# ATmega16HVBrevB device description
Architecture: AVR8; Family: megaAVR
Registers are 8-bit, access not given, no defined reset value unless marked. A register's access mark holds for its fields unless they carry their own. Offsets are from the block's base; [hi:lo] are bit positions.

## CELL_BALANCING
Instances: CELL_BALANCING 0x00
0xF1 CBCR — Cell Balancing Control Register
  [3:0] CBE (bit 1 of the value upward) — Cell Balancing Enables

## BATTERY_PROTECTION
Instances: BATTERY_PROTECTION 0x00
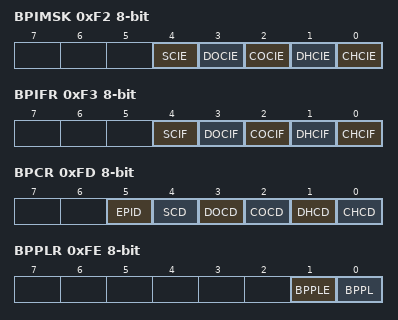
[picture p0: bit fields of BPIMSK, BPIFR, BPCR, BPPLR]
0xF2 BPIMSK — Battery Protection Interrupt Mask Register
  [4] SCIE — Short-circuit Protection Activated Interrupt Enable
  [3] DOCIE — Discharge Over-current Protection Activated Interrupt Enable
  [2] COCIE — Charge Over-current Protection Activated Interrupt Enable
  [1] DHCIE — Discharger High-current Protection Activated Interrupt
  [0] CHCIE — Charger High-current Protection Activated Interrupt
0xF3 BPIFR — Battery Protection Interrupt Flag Register
  [4] SCIF — Short-circuit Protection Activated Interrupt Flag
  [3] DOCIF — Discharge Over-current Protection Activated Interrupt Flag
  [2] COCIF — Charge Over-current Protection Activated Interrupt Flag
  [1] DHCIF — Disharge High-current Protection Activated Interrupt
  [0] CHCIF — Charge High-current Protection Activated Interrupt
0xF5 BPSCD — Battery Protection Short-Circuit Detection Level Register
  [7:0] SCDL — Battery Protection Short-Circuit Detection Level Register bits
0xF6 BPDOCD — Battery Protection Discharge-Over-current Detection Level Register
  [7:0] DOCDL — Battery Protection Discharge-Over-current Detection Level bits
0xF7 BPCOCD — Battery Protection Charge-Over-current Detection Level Register
  [7:0] COCDL — Battery Protection Charge-Over-current Detection Level bits
0xF8 BPDHCD — Battery Protection Discharge-High-current Detection Level Register
  [7:0] DHCDL — Battery Protection Discharge-High-current Detection Level bits
0xF9 BPCHCD — Battery Protection Charge-High-current Detection Level Register
  [7:0] CHCDL — Battery Protection Charge-High-current Detection Level bits
0xFA BPSCTR — Battery Protection Short-current Timing Register
  [6:0] SCPT — Battery Protection Short-current Timing bits
0xFB BPOCTR — Battery Protection Over-current Timing Register
  [5:0] OCPT — Battery Protection Over-current Timing bits
0xFC BPHCTR — Battery Protection Short-current Timing Register
  [5:0] HCPT — Battery Protection Short-current Timing bits
0xFD BPCR — Battery Protection Control Register
  [5] EPID — External Protection Input Disable
  [4] SCD — Short Circuit Protection Disabled
  [3] DOCD — Discharge Over-current Protection Disabled
  [2] COCD — Charge Over-current Protection Disabled
  [1] DHCD — Discharge High-current Protection Disable
  [0] CHCD — Charge High-current Protection Disable
0xFE BPPLR — Battery Protection Parameter Lock Register
  [1] BPPLE — Battery Protection Parameter Lock Enable
  [0] BPPL — Battery Protection Parameter Lock

## CHARGER_DETECT
Instances: CHARGER_DETECT 0x00
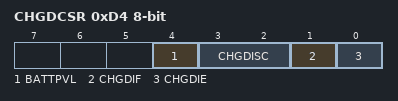
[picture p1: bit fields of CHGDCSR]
0xD4 CHGDCSR — Charger Detect Control and Status Register
  [4] BATTPVL — BATT Pin Voltage Level
  [3:2] CHGDISC — Charger Detect Interrupt Sense Control
  [1] CHGDIF — Charger Detect Interrupt Flag
  [0] CHGDIE — Charger Detect Interrupt Enable

## VOLTAGE_REGULATOR
Instances: VOLTAGE_REGULATOR 0x00
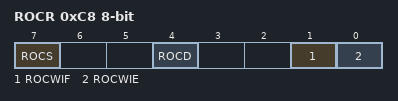
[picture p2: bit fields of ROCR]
0xC8 ROCR — Regulator Operating Condition Register
  [7] ROCS — ROC Status
  [4] ROCD — ROC Disable
  [1] ROCWIF — ROC Warning Interrupt Flag
  [0] ROCWIE — ROC Warning Interrupt Enable

## BANDGAP
Instances: BANDGAP 0x00
0xD0 BGCCR — Bandgap Calibration Register
  [5:0] BGCC — BG Calibration of PTAT Current Bits
0xD1 BGCRR — Bandgap Calibration of Resistor Ladder
  [7:0] BGCR — Bandgap Calibration of Resistor Ladder Bits
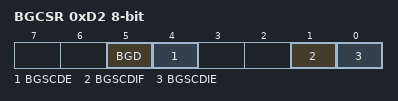
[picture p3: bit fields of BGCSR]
0xD2 BGCSR — Bandgap Control and Status Register
  [5] BGD — Bandgap Disable
  [4] BGSCDE — Bandgap Short Circuit Detection Enabled
  [1] BGSCDIF — Bandgap Short Circuit Detection Interrupt Flag
  [0] BGSCDIE — Bandgap Short Circuit Detection Interrupt Enable

## CPU — CPU Registers
Instances: CPU 0x00
Parameters: CORE_VERSION=V2E
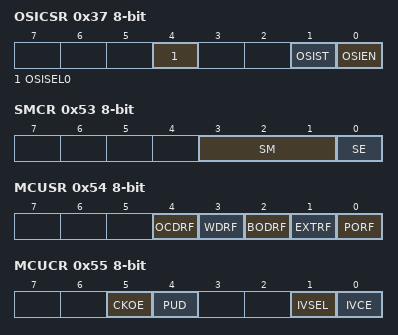
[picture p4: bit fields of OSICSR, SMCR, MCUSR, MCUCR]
0x37 OSICSR — Oscillator Sampling Interface Control and Status Register
  [4] OSISEL0 — Oscillator Sampling Interface Select 0
  [1] OSIST — Oscillator Sampling Interface Status
  [0] OSIEN — Oscillator Sampling Interface Enable
0x3E GPIOR0 — General Purpose IO Register 0
  [7:0] GPIOR0 — General Purpose IO bits
0x4A GPIOR1 — General Purpose IO Register 1
  [7:0] GPIOR1 — General Purpose IO bits
0x4B GPIOR2 — General Purpose IO Register 2
  [7:0] GPIOR2 — General Purpose IO bits
0x53 SMCR — Sleep Mode Control Register
  [3:1] SM — Sleep Mode Select bits
    0=IDLE; 1=ADC; 3=PSAVE (Power Save); 4=POFF (Power Off)
  [0] SE — Sleep Enable
0x54 MCUSR — MCU Status Register
  [4] OCDRF — OCD Reset Flag
  [3] WDRF — Watchdog Reset Flag
  [2] BODRF — Brown-out Reset Flag
  [1] EXTRF — External Reset Flag
  [0] PORF — Power-on reset flag
0x55 MCUCR — MCU Control Register
  [5] CKOE — Clock Output Enable
  [4] PUD — Pull-up disable
  [1] IVSEL — Interrupt Vector Select
  [0] IVCE — Interrupt Vector Change Enable
0x5D SP 16-bit — Stack Pointer
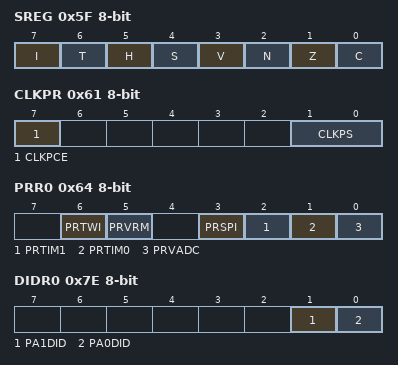
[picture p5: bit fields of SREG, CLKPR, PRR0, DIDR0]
0x5F SREG — Status Register
  [7] I — Global Interrupt Enable
  [6] T — Bit Copy Storage
  [5] H — Half Carry Flag
  [4] S — Sign Bit
  [3] V — Two's Complement Overflow Flag
  [2] N — Negative Flag
  [1] Z — Zero Flag
  [0] C — Carry Flag
0x61 CLKPR — Clock Prescale Register
  [7] CLKPCE — Clock Prescaler Change Enable
  [1:0] CLKPS — Clock Prescaler Select Bits
0x64 PRR0 — Power Reduction Register 0
  [6] PRTWI — Power Reduction TWI
  [5] PRVRM — Power Reduction Voltage Regulator Monitor
  [3] PRSPI — Power reduction SPI
  [2] PRTIM1 — Power Reduction Timer/Counter1
  [1] PRTIM0 — Power Reduction Timer/Counter0
  [0] PRVADC — Power Reduction V-ADC
0x66 FOSCCAL — Fast Oscillator Calibration Value
  [7:0] FCAL
0x7E DIDR0 — Digital Input Disable Register
  [1] PA1DID — When this bit is written logic one, the digital input buffer of the corresponding V_ADC pin is disabled.
  [0] PA0DID — When this bit is written logic one, the digital input buffer of the corresponding V_ADC pin is disabled.

## PORTA — I/O Port
Instances: PORTA 0x00
0x20 PINA bits used 3:0 — Port A Input Pins
0x21 DDRA bits used 3:0 — Port A Data Direction Register
0x22 PORTA bits used 3:0 — Port A Data Register

## PORTB — I/O Port
Instances: PORTB 0x00
0x23 PINB — Port B Input Pins
0x24 DDRB — Port B Data Direction Register
0x25 PORTB — Port B Data Register

## PORTC — I/O Port
Instances: PORTC 0x00
0x26 PINC bits used 4:0 — Port C Input Pins
0x28 PORTC bits used 5:0 — Port C Data Register

## BOOT_LOAD — Bootloader
Instances: BOOT_LOAD 0x00
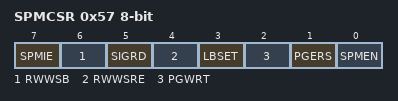
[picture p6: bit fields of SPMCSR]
0x57 SPMCSR — Store Program Memory Control and Status Register
  [7] SPMIE — SPM Interrupt Enable
  [6] RWWSB — Read-While-Write Section Busy
  [5] SIGRD — Signature Row Read
  [4] RWWSRE — Read-While-Write Section Read Enable
  [3] LBSET — Lock Bit Set
  [2] PGWRT — Page Write
  [1] PGERS — Page Erase
  [0] SPMEN — Store Program Memory Enable
